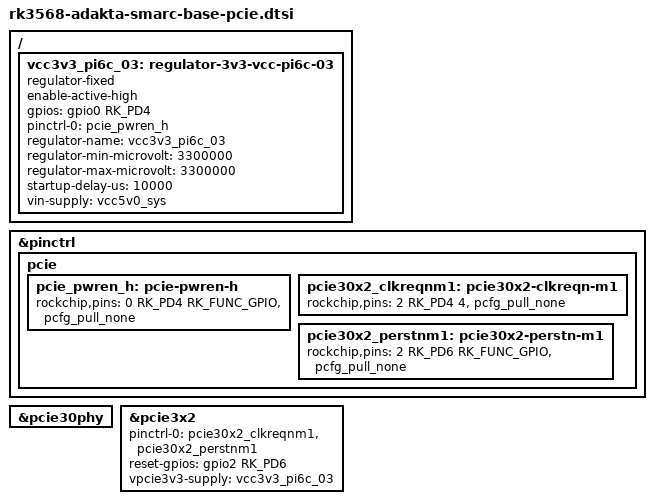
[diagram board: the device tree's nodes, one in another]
// SPDX-License-Identifier: (GPL-2.0+ OR MIT)
/*
 * Copyright (c) 2024 Adakta, Ltd.
 *
 */

/ {
	/* pi6c pcie clock generator */
	vcc3v3_pi6c_03: regulator-3v3-vcc-pi6c-03 {
		compatible = "regulator-fixed";
		enable-active-high;
		gpios = <&gpio0 RK_PD4 GPIO_ACTIVE_HIGH>;
		pinctrl-names = "default";
		pinctrl-0 = <&pcie_pwren_h>;
		regulator-name = "vcc3v3_pi6c_03";
		regulator-min-microvolt = <3300000>;
		regulator-max-microvolt = <3300000>;
		startup-delay-us = <10000>;
		vin-supply = <&vcc5v0_sys>;
	};
};

&pinctrl {
	pcie {
		/omit-if-no-ref/
		pcie_pwren_h: pcie-pwren-h {
			rockchip,pins = <0 RK_PD4 RK_FUNC_GPIO &pcfg_pull_none>;
		};

		/* PCI_A + PCI_B */
		pcie30x2_clkreqnm1: pcie30x2-clkreqn-m1 {
			rockchip,pins = <2 RK_PD4 4 &pcfg_pull_none>;
		};

		/* PCI_A + PCI_B */
		pcie30x2_perstnm1: pcie30x2-perstn-m1 {
			rockchip,pins = <2 RK_PD6 RK_FUNC_GPIO &pcfg_pull_none>;
		};
	};
};

&pcie30phy {
	status = "okay";
};

/* PCI_A + PCI_B */
&pcie3x2 {
	pinctrl-names = "default";
	pinctrl-0 = <&pcie30x2_clkreqnm1 &pcie30x2_perstnm1>;
	reset-gpios = <&gpio2 RK_PD6 GPIO_ACTIVE_HIGH>;
	vpcie3v3-supply = <&vcc3v3_pi6c_03>;
	status = "okay";
};
